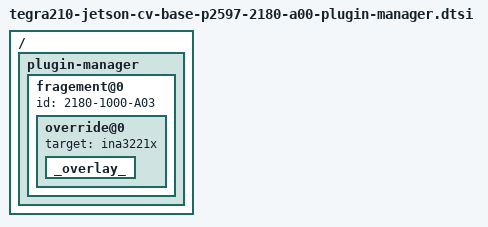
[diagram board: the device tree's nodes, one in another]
/*
 * tegra210-jetson-cv-base-p2597-2180-a00-plugin-manager.dtsi: P2597 plugin manager
 *
 * Copyright (c) 2015, NVIDIA CORPORATION.  All rights reserved.
 *
 * This program is free software; you can redistribute it and/or modify
 * it under the terms of the GNU General Public License as published by
 * the Free Software Foundation; version 2 of the License.
 *
 * This program is distributed in the hope that it will be useful, but WITHOUT
 * ANY WARRANTY; without even the implied warranty of MERCHANTABILITY or
 * FITNESS FOR A PARTICULAR PURPOSE.  See the GNU General Public License for
 * more details.
 */

/ {
	plugin-manager {
		fragement@0 {
			id = "2180-1000-A03";
			override@0 {
				target = <&ina3221x>;
				_overlay_ {
					status = "okay";
				};
			};
		};
	};
};

